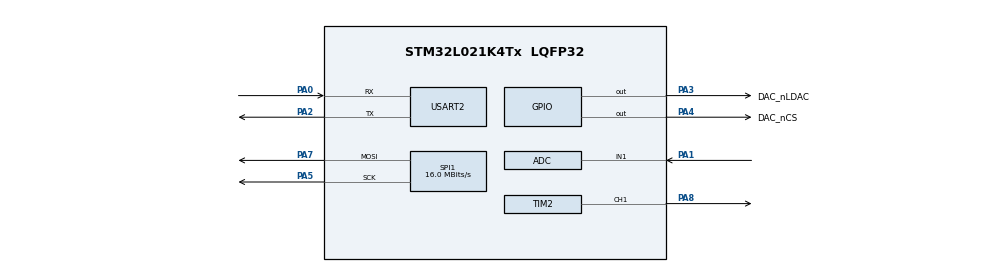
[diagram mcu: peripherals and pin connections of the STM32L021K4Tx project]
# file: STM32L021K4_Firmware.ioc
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Mcu.Family=STM32L0
Mcu.Name=STM32L021K4Tx
Mcu.Package=LQFP32
NVIC.TIM21_IRQn=true\:0\:0\:false\:false\:true\:true\:true\:true
PA0-CK_IN.Mode=Asynchronous
PA0-CK_IN.Signal=USART2_RX
PA1.Mode=IN1
PA1.Signal=ADC_IN1
PA13.Mode=Serial_Wire
PA13.Signal=SYS_SWDIO
PA14.Mode=Serial_Wire
PA14.Signal=SYS_SWCLK
PA2.Mode=Asynchronous
PA2.Signal=USART2_TX
PA3.GPIO_Label=DAC_nLDAC
PA3.Signal=GPIO_Output
PA4.GPIO_Label=DAC_nCS
PA4.Signal=GPIO_Output
PA5.Mode=TX_Only_Simplex_Unidirect_Master
PA5.Signal=SPI1_SCK
PA7.Mode=TX_Only_Simplex_Unidirect_Master
PA7.Signal=SPI1_MOSI
PA8.Signal=S_TIM2_CH1
ProjectManager.HeapSize=0x200
ProjectManager.StackSize=0x400
ProjectManager.TargetToolchain=STM32CubeIDE
RCC.ADCFreq_Value=16000000
RCC.AHBFreq_Value=32000000
RCC.APB1Freq_Value=32000000
RCC.APB1TimFreq_Value=32000000
RCC.APB2Freq_Value=32000000
RCC.APB2TimFreq_Value=32000000
RCC.HCLKFreq_Value=32000000
RCC.HSE_VALUE=8000000
RCC.HSI16_VALUE=16000000
RCC.HSI_VALUE=16000000
RCC.LSE_VALUE=32768
RCC.MSI_VALUE=2097000
RCC.PLLMUL=RCC_PLLMUL_4
RCC.SYSCLKFreq_VALUE=32000000
RCC.SYSCLKSource=RCC_SYSCLKSOURCE_PLLCLK
RCC.Usart2ClockSelection=RCC_USART2CLKSOURCE_SYSCLK
RCC.VCOOutputFreq_Value=64000000
SH.S_TIM2_CH1.0=TIM2_CH1,PWM Generation1 CH1
SPI1.CalculateBaudRate=16.0 MBits/s
SPI1.Direction=SPI_DIRECTION_2LINES
SPI1.Mode=SPI_MODE_MASTER
SPI1.VirtualType=VM_MASTER
TIM2.Channel-PWM\ Generation1\ CH1=TIM_CHANNEL_1
TIM2.Period=255
TIM2.Prescaler=124
TIM21.Period=1000
USART2.VirtualMode-Asynchronous=VM_ASYNC
VP_TIM21_VS_ClockSourceINT.Mode=Internal
VP_TIM2_VS_ClockSourceINT.Mode=Internal
board=custom

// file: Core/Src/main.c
/* USER CODE BEGIN Header */
/**
  ******************************************************************************
  * @file           : main.c
  * @brief          : Main program body
  ******************************************************************************
  * @attention
  *
  * Copyright (c) 2024 STMicroelectronics.
  * All rights reserved.
  *
  * This software is licensed under terms that can be found in the LICENSE file
  * in the root directory of this software component.
  * If no LICENSE file comes with this software, it is provided AS-IS.
  *
  ******************************************************************************
  */
/* USER CODE END Header */
#include "main.h"

void SystemClock_Config(void);
static void MX_GPIO_Init(void);
static void MX_USART2_UART_Init(void);
static void MX_ADC_Init(void);
static void MX_SPI1_Init(void);
static void MX_TIM2_Init(void);
static void MX_TIM21_Init(void);

int main(void)
{

  /* MCU Configuration--------------------------------------------------------*/

  /* Reset of all peripherals, Initializes the Flash interface and the Systick. */
  LL_APB2_GRP1_EnableClock(LL_APB2_GRP1_PERIPH_SYSCFG);
  LL_APB1_GRP1_EnableClock(LL_APB1_GRP1_PERIPH_PWR);

  /* SysTick_IRQn interrupt configuration */
  NVIC_SetPriority(SysTick_IRQn, 3);

  /* Configure the system clock */
  SystemClock_Config();

  /* Initialize all configured peripherals */
  MX_GPIO_Init();
  MX_USART2_UART_Init();
  MX_ADC_Init();
  MX_SPI1_Init();
  MX_TIM2_Init();
  MX_TIM21_Init();
  /* USER CODE BEGIN 2 */
  LedStart();
  TimeBaseStartIT();
  AnalogOutInit();

  hShell_t hShell;

  ShellInit(&hShell, &SerialTransmit);
  /* USER CODE END 2 */

  /* Infinite loop */
  while (1)
  {

  }
}

void SystemClock_Config(void)
{
  LL_FLASH_SetLatency(LL_FLASH_LATENCY_1);
  while(LL_FLASH_GetLatency()!= LL_FLASH_LATENCY_1)
  {
  }
  LL_PWR_SetRegulVoltageScaling(LL_PWR_REGU_VOLTAGE_SCALE1);
  while (LL_PWR_IsActiveFlag_VOS() != 0)
  {
  }
  LL_RCC_HSI_Enable();

   /* Wait till HSI is ready */
  while(LL_RCC_HSI_IsReady() != 1)
  {

  }
  LL_RCC_HSI_SetCalibTrimming(16);
  LL_RCC_PLL_ConfigDomain_SYS(LL_RCC_PLLSOURCE_HSI, LL_RCC_PLL_MUL_4, LL_RCC_PLL_DIV_2);
  LL_RCC_PLL_Enable();

   /* Wait till PLL is ready */
  while(LL_RCC_PLL_IsReady() != 1)
  {

  }
  LL_RCC_SetAHBPrescaler(LL_RCC_SYSCLK_DIV_1);
  LL_RCC_SetAPB1Prescaler(LL_RCC_APB1_DIV_1);
  LL_RCC_SetAPB2Prescaler(LL_RCC_APB2_DIV_1);
  LL_RCC_SetSysClkSource(LL_RCC_SYS_CLKSOURCE_PLL);

   /* Wait till System clock is ready */
  while(LL_RCC_GetSysClkSource() != LL_RCC_SYS_CLKSOURCE_STATUS_PLL)
  {

  }

  LL_Init1msTick(32000000);

  LL_SetSystemCoreClock(32000000);
  LL_RCC_SetUSARTClockSource(LL_RCC_USART2_CLKSOURCE_SYSCLK);
}

static void MX_ADC_Init(void)
{

  LL_ADC_REG_InitTypeDef ADC_REG_InitStruct = {0};
  LL_ADC_InitTypeDef ADC_InitStruct = {0};

  LL_GPIO_InitTypeDef GPIO_InitStruct = {0};

  /* Peripheral clock enable */
  LL_APB2_GRP1_EnableClock(LL_APB2_GRP1_PERIPH_ADC1);

  LL_IOP_GRP1_EnableClock(LL_IOP_GRP1_PERIPH_GPIOA);
  /**ADC GPIO Configuration
  PA1   ------> ADC_IN1
  */
  GPIO_InitStruct.Pin = LL_GPIO_PIN_1;
  GPIO_InitStruct.Mode = LL_GPIO_MODE_ANALOG;
  GPIO_InitStruct.Pull = LL_GPIO_PULL_NO;
  LL_GPIO_Init(GPIOA, &GPIO_InitStruct);

  /** Configure Regular Channel
  */
  LL_ADC_REG_SetSequencerChAdd(ADC1, LL_ADC_CHANNEL_1);

  /** Common config
  */
  ADC_REG_InitStruct.TriggerSource = LL_ADC_REG_TRIG_SOFTWARE;
  ADC_REG_InitStruct.SequencerDiscont = LL_ADC_REG_SEQ_DISCONT_DISABLE;
  ADC_REG_InitStruct.ContinuousMode = LL_ADC_REG_CONV_SINGLE;
  ADC_REG_InitStruct.DMATransfer = LL_ADC_REG_DMA_TRANSFER_NONE;
  ADC_REG_InitStruct.Overrun = LL_ADC_REG_OVR_DATA_PRESERVED;
  LL_ADC_REG_Init(ADC1, &ADC_REG_InitStruct);
  LL_ADC_SetSamplingTimeCommonChannels(ADC1, LL_ADC_SAMPLINGTIME_1CYCLE_5);
  LL_ADC_SetOverSamplingScope(ADC1, LL_ADC_OVS_DISABLE);
  LL_ADC_REG_SetSequencerScanDirection(ADC1, LL_ADC_REG_SEQ_SCAN_DIR_FORWARD);
  LL_ADC_SetCommonFrequencyMode(__LL_ADC_COMMON_INSTANCE(ADC1), LL_ADC_CLOCK_FREQ_MODE_HIGH);
  LL_ADC_DisableIT_EOC(ADC1);
  LL_ADC_DisableIT_EOS(ADC1);
  ADC_InitStruct.Clock = LL_ADC_CLOCK_SYNC_PCLK_DIV2;
  ADC_InitStruct.Resolution = LL_ADC_RESOLUTION_12B;
  ADC_InitStruct.DataAlignment = LL_ADC_DATA_ALIGN_RIGHT;
  ADC_InitStruct.LowPowerMode = LL_ADC_LP_MODE_NONE;
  LL_ADC_Init(ADC1, &ADC_InitStruct);

  /* Enable ADC internal voltage regulator */
  LL_ADC_EnableInternalRegulator(ADC1);
  /* Delay for ADC internal voltage regulator stabilization. */
  /* Compute number of CPU cycles to wait for, from delay in us. */
  /* Note: Variable divided by 2 to compensate partially */
  /* CPU processing cycles (depends on compilation optimization). */
  /* Note: If system core clock frequency is below 200kHz, wait time */
  /* is only a few CPU processing cycles. */
  uint32_t wait_loop_index;
  wait_loop_index = ((LL_ADC_DELAY_INTERNAL_REGUL_STAB_US * (SystemCoreClock / (100000 * 2))) / 10);
  while(wait_loop_index != 0)
  {
    wait_loop_index--;
  }

}

static void MX_SPI1_Init(void)
{

  LL_SPI_InitTypeDef SPI_InitStruct = {0};

  LL_GPIO_InitTypeDef GPIO_InitStruct = {0};

  /* Peripheral clock enable */
  LL_APB2_GRP1_EnableClock(LL_APB2_GRP1_PERIPH_SPI1);

  LL_IOP_GRP1_EnableClock(LL_IOP_GRP1_PERIPH_GPIOA);
  /**SPI1 GPIO Configuration
  PA5   ------> SPI1_SCK
  PA7   ------> SPI1_MOSI
  */
  GPIO_InitStruct.Pin = LL_GPIO_PIN_5;
  GPIO_InitStruct.Mode = LL_GPIO_MODE_ALTERNATE;
  GPIO_InitStruct.Speed = LL_GPIO_SPEED_FREQ_VERY_HIGH;
  GPIO_InitStruct.OutputType = LL_GPIO_OUTPUT_PUSHPULL;
  GPIO_InitStruct.Pull = LL_GPIO_PULL_NO;
  GPIO_InitStruct.Alternate = LL_GPIO_AF_0;
  LL_GPIO_Init(GPIOA, &GPIO_InitStruct);

  GPIO_InitStruct.Pin = LL_GPIO_PIN_7;
  GPIO_InitStruct.Mode = LL_GPIO_MODE_ALTERNATE;
  GPIO_InitStruct.Speed = LL_GPIO_SPEED_FREQ_VERY_HIGH;
  GPIO_InitStruct.OutputType = LL_GPIO_OUTPUT_PUSHPULL;
  GPIO_InitStruct.Pull = LL_GPIO_PULL_NO;
  GPIO_InitStruct.Alternate = LL_GPIO_AF_0;
  LL_GPIO_Init(GPIOA, &GPIO_InitStruct);

  /* SPI1 parameter configuration*/
  SPI_InitStruct.TransferDirection = LL_SPI_FULL_DUPLEX;
  SPI_InitStruct.Mode = LL_SPI_MODE_MASTER;
  SPI_InitStruct.DataWidth = LL_SPI_DATAWIDTH_8BIT;
  SPI_InitStruct.ClockPolarity = LL_SPI_POLARITY_LOW;
  SPI_InitStruct.ClockPhase = LL_SPI_PHASE_1EDGE;
  SPI_InitStruct.NSS = LL_SPI_NSS_SOFT;
  SPI_InitStruct.BaudRate = LL_SPI_BAUDRATEPRESCALER_DIV2;
  SPI_InitStruct.BitOrder = LL_SPI_MSB_FIRST;
  SPI_InitStruct.CRCCalculation = LL_SPI_CRCCALCULATION_DISABLE;
  SPI_InitStruct.CRCPoly = 7;
  LL_SPI_Init(SPI1, &SPI_InitStruct);
  LL_SPI_SetStandard(SPI1, LL_SPI_PROTOCOL_MOTOROLA);

}

static void MX_TIM2_Init(void)
{

  LL_TIM_InitTypeDef TIM_InitStruct = {0};
  LL_TIM_OC_InitTypeDef TIM_OC_InitStruct = {0};

  LL_GPIO_InitTypeDef GPIO_InitStruct = {0};

  /* Peripheral clock enable */
  LL_APB1_GRP1_EnableClock(LL_APB1_GRP1_PERIPH_TIM2);

  TIM_InitStruct.Prescaler = 124;
  TIM_InitStruct.CounterMode = LL_TIM_COUNTERMODE_UP;
  TIM_InitStruct.Autoreload = 255;
  TIM_InitStruct.ClockDivision = LL_TIM_CLOCKDIVISION_DIV1;
  LL_TIM_Init(TIM2, &TIM_InitStruct);
  LL_TIM_DisableARRPreload(TIM2);
  LL_TIM_SetClockSource(TIM2, LL_TIM_CLOCKSOURCE_INTERNAL);
  LL_TIM_OC_EnablePreload(TIM2, LL_TIM_CHANNEL_CH1);
  TIM_OC_InitStruct.OCMode = LL_TIM_OCMODE_PWM1;
  TIM_OC_InitStruct.OCState = LL_TIM_OCSTATE_DISABLE;
  TIM_OC_InitStruct.CompareValue = 0;
  TIM_OC_InitStruct.OCPolarity = LL_TIM_OCPOLARITY_HIGH;
  LL_TIM_OC_Init(TIM2, LL_TIM_CHANNEL_CH1, &TIM_OC_InitStruct);
  LL_TIM_OC_DisableFast(TIM2, LL_TIM_CHANNEL_CH1);
  LL_TIM_SetTriggerOutput(TIM2, LL_TIM_TRGO_RESET);
  LL_TIM_DisableMasterSlaveMode(TIM2);
  LL_IOP_GRP1_EnableClock(LL_IOP_GRP1_PERIPH_GPIOA);
  /**TIM2 GPIO Configuration
  PA8   ------> TIM2_CH1
  */
  GPIO_InitStruct.Pin = LL_GPIO_PIN_8;
  GPIO_InitStruct.Mode = LL_GPIO_MODE_ALTERNATE;
  GPIO_InitStruct.Speed = LL_GPIO_SPEED_FREQ_LOW;
  GPIO_InitStruct.OutputType = LL_GPIO_OUTPUT_PUSHPULL;
  GPIO_InitStruct.Pull = LL_GPIO_PULL_NO;
  GPIO_InitStruct.Alternate = LL_GPIO_AF_5;
  LL_GPIO_Init(GPIOA, &GPIO_InitStruct);

}

static void MX_TIM21_Init(void)
{

  LL_TIM_InitTypeDef TIM_InitStruct = {0};

  /* Peripheral clock enable */
  LL_APB2_GRP1_EnableClock(LL_APB2_GRP1_PERIPH_TIM21);

  /* TIM21 interrupt Init */
  NVIC_SetPriority(TIM21_IRQn, 0);
  NVIC_EnableIRQ(TIM21_IRQn);

  TIM_InitStruct.Prescaler = 0;
  TIM_InitStruct.CounterMode = LL_TIM_COUNTERMODE_UP;
  TIM_InitStruct.Autoreload = 1000;
  TIM_InitStruct.ClockDivision = LL_TIM_CLOCKDIVISION_DIV1;
  LL_TIM_Init(TIM21, &TIM_InitStruct);
  LL_TIM_DisableARRPreload(TIM21);
  LL_TIM_SetClockSource(TIM21, LL_TIM_CLOCKSOURCE_INTERNAL);
  LL_TIM_SetTriggerOutput(TIM21, LL_TIM_TRGO_RESET);
  LL_TIM_DisableMasterSlaveMode(TIM21);

}

static void MX_USART2_UART_Init(void)
{

  LL_USART_InitTypeDef USART_InitStruct = {0};

  LL_GPIO_InitTypeDef GPIO_InitStruct = {0};

  /* Peripheral clock enable */
  LL_APB1_GRP1_EnableClock(LL_APB1_GRP1_PERIPH_USART2);

  LL_IOP_GRP1_EnableClock(LL_IOP_GRP1_PERIPH_GPIOA);
  /**USART2 GPIO Configuration
  PA0-CK_IN   ------> USART2_RX
  PA2   ------> USART2_TX
  */
  GPIO_InitStruct.Pin = LL_GPIO_PIN_0;
  GPIO_InitStruct.Mode = LL_GPIO_MODE_ALTERNATE;
  GPIO_InitStruct.Speed = LL_GPIO_SPEED_FREQ_VERY_HIGH;
  GPIO_InitStruct.OutputType = LL_GPIO_OUTPUT_PUSHPULL;
  GPIO_InitStruct.Pull = LL_GPIO_PULL_NO;
  GPIO_InitStruct.Alternate = LL_GPIO_AF_0;
  LL_GPIO_Init(GPIOA, &GPIO_InitStruct);

  GPIO_InitStruct.Pin = LL_GPIO_PIN_2;
  GPIO_InitStruct.Mode = LL_GPIO_MODE_ALTERNATE;
  GPIO_InitStruct.Speed = LL_GPIO_SPEED_FREQ_VERY_HIGH;
  GPIO_InitStruct.OutputType = LL_GPIO_OUTPUT_PUSHPULL;
  GPIO_InitStruct.Pull = LL_GPIO_PULL_NO;
  GPIO_InitStruct.Alternate = LL_GPIO_AF_4;
  LL_GPIO_Init(GPIOA, &GPIO_InitStruct);

  USART_InitStruct.BaudRate = 115200;
  USART_InitStruct.DataWidth = LL_USART_DATAWIDTH_8B;
  USART_InitStruct.StopBits = LL_USART_STOPBITS_1;
  USART_InitStruct.Parity = LL_USART_PARITY_NONE;
  USART_InitStruct.TransferDirection = LL_USART_DIRECTION_TX_RX;
  USART_InitStruct.HardwareFlowControl = LL_USART_HWCONTROL_NONE;
  USART_InitStruct.OverSampling = LL_USART_OVERSAMPLING_16;
  LL_USART_Init(USART2, &USART_InitStruct);
  LL_USART_ConfigAsyncMode(USART2);
  LL_USART_Enable(USART2);

}

static void MX_GPIO_Init(void)
{
  LL_GPIO_InitTypeDef GPIO_InitStruct = {0};

  /* GPIO Ports Clock Enable */
  LL_IOP_GRP1_EnableClock(LL_IOP_GRP1_PERIPH_GPIOA);

  /**/
  LL_GPIO_ResetOutputPin(DAC_nLDAC_GPIO_Port, DAC_nLDAC_Pin);

  /**/
  LL_GPIO_ResetOutputPin(DAC_nCS_GPIO_Port, DAC_nCS_Pin);

  /**/
  GPIO_InitStruct.Pin = DAC_nLDAC_Pin;
  GPIO_InitStruct.Mode = LL_GPIO_MODE_OUTPUT;
  GPIO_InitStruct.Speed = LL_GPIO_SPEED_FREQ_LOW;
  GPIO_InitStruct.OutputType = LL_GPIO_OUTPUT_PUSHPULL;
  GPIO_InitStruct.Pull = LL_GPIO_PULL_NO;
  LL_GPIO_Init(DAC_nLDAC_GPIO_Port, &GPIO_InitStruct);

  /**/
  GPIO_InitStruct.Pin = DAC_nCS_Pin;
  GPIO_InitStruct.Mode = LL_GPIO_MODE_OUTPUT;
  GPIO_InitStruct.Speed = LL_GPIO_SPEED_FREQ_LOW;
  GPIO_InitStruct.OutputType = LL_GPIO_OUTPUT_PUSHPULL;
  GPIO_InitStruct.Pull = LL_GPIO_PULL_NO;
  LL_GPIO_Init(DAC_nCS_GPIO_Port, &GPIO_InitStruct);

}

void Error_Handler(void)
{
  __disable_irq();
  while (1)
  {
  }
}
